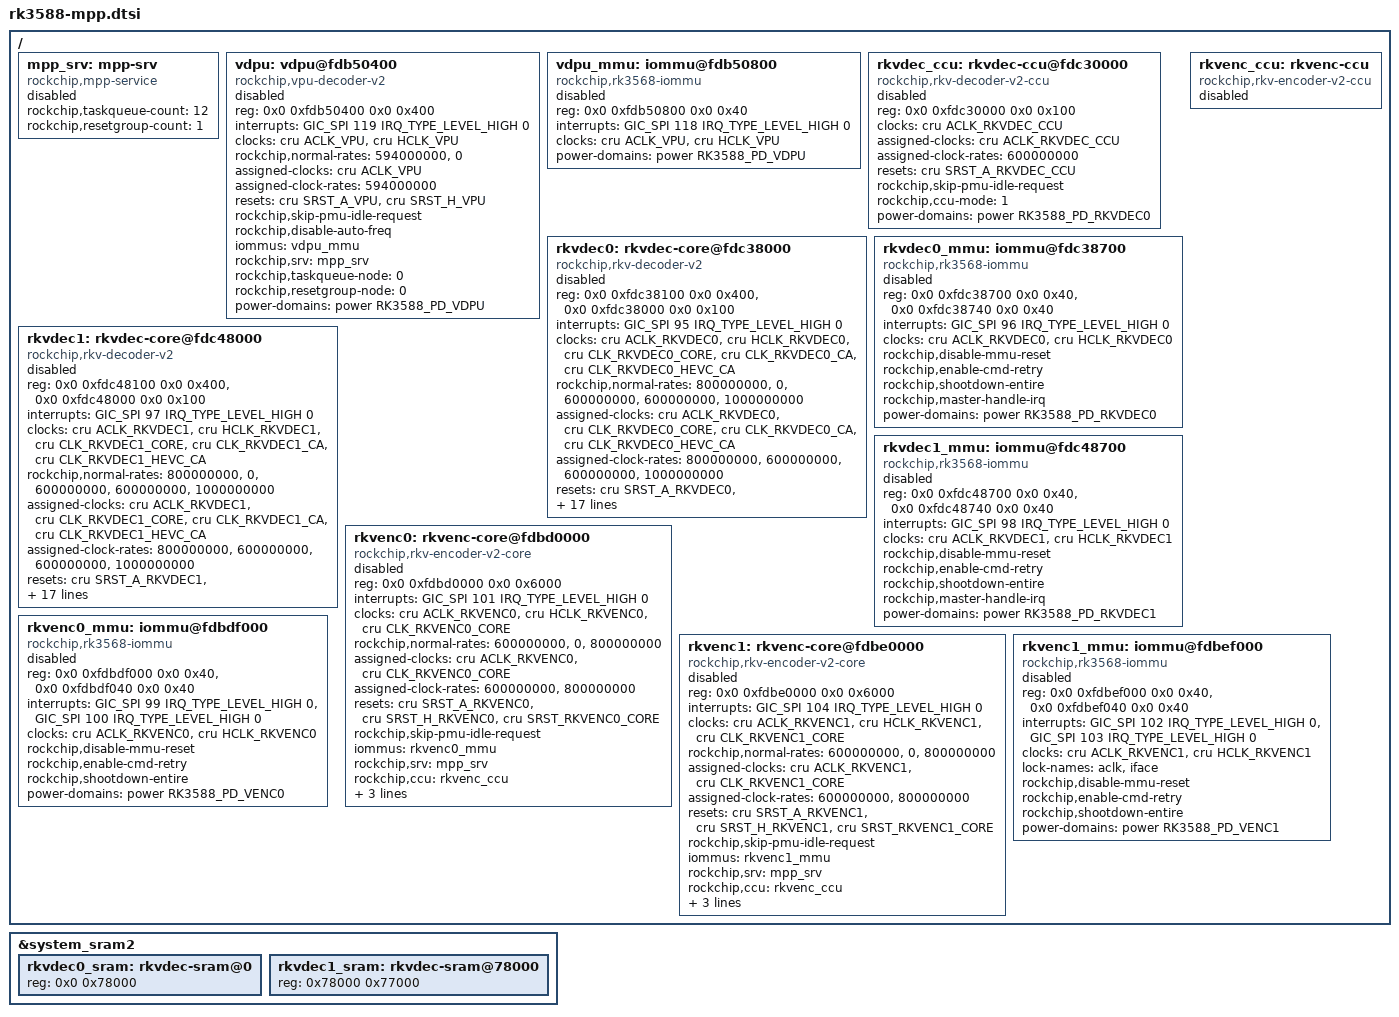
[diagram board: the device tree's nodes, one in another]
// SPDX-License-Identifier: (GPL-2.0+ OR MIT)
/ {
    mpp_srv: mpp-srv {
        compatible = "rockchip,mpp-service";
        rockchip,taskqueue-count = <12>;
        rockchip,resetgroup-count = <1>;
        status = "disabled";
    };

    vdpu: vdpu@fdb50400 {
        compatible = "rockchip,vpu-decoder-v2";
        reg = <0x0 0xfdb50400 0x0 0x400>;
        interrupts = <GIC_SPI 119 IRQ_TYPE_LEVEL_HIGH 0>;
        interrupt-names = "irq_vdpu";
        clocks = <&cru ACLK_VPU>, <&cru HCLK_VPU>;
        clock-names = "aclk_vcodec", "hclk_vcodec";
        rockchip,normal-rates = <594000000>, <0>;
        assigned-clocks = <&cru ACLK_VPU>;
        assigned-clock-rates = <594000000>;
        resets = <&cru SRST_A_VPU>, <&cru SRST_H_VPU>;
        reset-names = "shared_video_a", "shared_video_h";
        rockchip,skip-pmu-idle-request;
        rockchip,disable-auto-freq;
        iommus = <&vdpu_mmu>;
        rockchip,srv = <&mpp_srv>;
        rockchip,taskqueue-node = <0>;
        rockchip,resetgroup-node = <0>;
        power-domains = <&power RK3588_PD_VDPU>;
        status = "disabled";
    };

    vdpu_mmu: iommu@fdb50800 {
        compatible = "rockchip,rk3568-iommu";
        reg = <0x0 0xfdb50800 0x0 0x40>;
        interrupts = <GIC_SPI 118 IRQ_TYPE_LEVEL_HIGH 0>;
        interrupt-names = "irq_vdpu_mmu";
        clocks = <&cru ACLK_VPU>, <&cru HCLK_VPU>;
        clock-names = "aclk", "iface";
        power-domains = <&power RK3588_PD_VDPU>;
        #iommu-cells = <0>;
        status = "disabled";
    };

    rkvdec_ccu: rkvdec-ccu@fdc30000 {
        compatible = "rockchip,rkv-decoder-v2-ccu";
        reg = <0x0 0xfdc30000 0x0 0x100>;
        reg-names = "ccu";
        clocks = <&cru ACLK_RKVDEC_CCU>;
        clock-names = "aclk_ccu";
        assigned-clocks = <&cru ACLK_RKVDEC_CCU>;
        assigned-clock-rates = <600000000>;
        resets = <&cru SRST_A_RKVDEC_CCU>;
        reset-names = "video_ccu";
        rockchip,skip-pmu-idle-request;
        /* 1: soft ccu 2: hw ccu */
        rockchip,ccu-mode = <1>;
        power-domains = <&power RK3588_PD_RKVDEC0>;
        status = "disabled";
    };

    rkvdec0: rkvdec-core@fdc38000 {
        compatible = "rockchip,rkv-decoder-v2";
        reg = <0x0 0xfdc38100 0x0 0x400>, <0x0 0xfdc38000 0x0 0x100>;
        reg-names = "regs", "link";
        interrupts = <GIC_SPI 95 IRQ_TYPE_LEVEL_HIGH 0>;
        interrupt-names = "irq_rkvdec0";
        clocks = <&cru ACLK_RKVDEC0>, <&cru HCLK_RKVDEC0>, <&cru CLK_RKVDEC0_CORE>,
             <&cru CLK_RKVDEC0_CA>, <&cru CLK_RKVDEC0_HEVC_CA>;
        clock-names = "aclk_vcodec", "hclk_vcodec", "clk_core",
                  "clk_cabac", "clk_hevc_cabac";
        rockchip,normal-rates = <800000000>, <0>, <600000000>,
                    <600000000>, <1000000000>;
        assigned-clocks = <&cru ACLK_RKVDEC0>, <&cru CLK_RKVDEC0_CORE>,
                  <&cru CLK_RKVDEC0_CA>, <&cru CLK_RKVDEC0_HEVC_CA>;
        assigned-clock-rates = <800000000>, <600000000>,
                       <600000000>, <1000000000>;
        resets = <&cru SRST_A_RKVDEC0>, <&cru SRST_H_RKVDEC0>, <&cru SRST_RKVDEC0_CORE>,
             <&cru SRST_RKVDEC0_CA>, <&cru SRST_RKVDEC0_HEVC_CA>;
        reset-names = "video_a", "video_h", "video_core",
                  "video_cabac", "video_hevc_cabac";
        rockchip,skip-pmu-idle-request;
        iommus = <&rkvdec0_mmu>;
        rockchip,srv = <&mpp_srv>;
        rockchip,ccu = <&rkvdec_ccu>;
        rockchip,core-mask = <0x00010001>;
        rockchip,task-capacity = <16>;
        rockchip,taskqueue-node = <9>;
        rockchip,sram = <&rkvdec0_sram>;
        /* rcb_iova: start and size 1M@4095M */
        rockchip,rcb-iova = <0xFFF00000 0x100000>;
        rockchip,rcb-info = <136 24576>, <137 49152>, <141 90112>, <140 49152>,
                    <139 180224>, <133 49152>, <134 8192>, <135 4352>,
                    <138 13056>, <142 291584>;
        rockchip,rcb-min-width = <512>;
        power-domains = <&power RK3588_PD_RKVDEC0>;
        status = "disabled";
    };

    rkvdec0_mmu: iommu@fdc38700 {
        compatible = "rockchip,rk3568-iommu";
        reg = <0x0 0xfdc38700 0x0 0x40>, <0x0 0xfdc38740 0x0 0x40>;
        interrupts = <GIC_SPI 96 IRQ_TYPE_LEVEL_HIGH 0>;
        interrupt-names = "irq_rkvdec0_mmu";
        clocks = <&cru ACLK_RKVDEC0>, <&cru HCLK_RKVDEC0>;
        clock-names = "aclk", "iface";
        rockchip,disable-mmu-reset;
        rockchip,enable-cmd-retry;
        rockchip,shootdown-entire;
        rockchip,master-handle-irq;
        #iommu-cells = <0>;
        power-domains = <&power RK3588_PD_RKVDEC0>;
        status = "disabled";
    };

    rkvdec1: rkvdec-core@fdc48000 {
        compatible = "rockchip,rkv-decoder-v2";
        reg = <0x0 0xfdc48100 0x0 0x400>, <0x0 0xfdc48000 0x0 0x100>;
        reg-names = "regs", "link";
        interrupts = <GIC_SPI 97 IRQ_TYPE_LEVEL_HIGH 0>;
        interrupt-names = "irq_rkvdec1";
        clocks = <&cru ACLK_RKVDEC1>, <&cru HCLK_RKVDEC1>, <&cru CLK_RKVDEC1_CORE>,
             <&cru CLK_RKVDEC1_CA>, <&cru CLK_RKVDEC1_HEVC_CA>;
        clock-names = "aclk_vcodec", "hclk_vcodec", "clk_core",
                  "clk_cabac", "clk_hevc_cabac";
        rockchip,normal-rates = <800000000>, <0>, <600000000>,
                    <600000000>, <1000000000>;
        assigned-clocks = <&cru ACLK_RKVDEC1>, <&cru CLK_RKVDEC1_CORE>,
                  <&cru CLK_RKVDEC1_CA>, <&cru CLK_RKVDEC1_HEVC_CA>;
        assigned-clock-rates = <800000000>, <600000000>,
                       <600000000>, <1000000000>;
        resets = <&cru SRST_A_RKVDEC1>, <&cru SRST_H_RKVDEC1>, <&cru SRST_RKVDEC1_CORE>,
             <&cru SRST_RKVDEC1_CA>, <&cru SRST_RKVDEC1_HEVC_CA>;
        reset-names = "video_a", "video_h", "video_core",
                  "video_cabac", "video_hevc_cabac";
        rockchip,skip-pmu-idle-request;
        iommus = <&rkvdec1_mmu>;
        rockchip,srv = <&mpp_srv>;
        rockchip,ccu = <&rkvdec_ccu>;
        rockchip,core-mask = <0x00020002>;
        rockchip,task-capacity = <16>;
        rockchip,taskqueue-node = <9>;
        rockchip,sram = <&rkvdec1_sram>;
        /* rcb_iova: start and size 1M@4094M */
        rockchip,rcb-iova = <0xFFE00000 0x100000>;
        rockchip,rcb-info = <136 24576>, <137 49152>, <141 90112>, <140 49152>,
                    <139 180224>, <133 49152>, <134 8192>, <135 4352>,
                    <138 13056>, <142 291584>;
        rockchip,rcb-min-width = <512>;
        power-domains = <&power RK3588_PD_RKVDEC1>;
        status = "disabled";
    };

    rkvdec1_mmu: iommu@fdc48700 {
        compatible = "rockchip,rk3568-iommu";
        reg = <0x0 0xfdc48700 0x0 0x40>, <0x0 0xfdc48740 0x0 0x40>;
        interrupts = <GIC_SPI 98 IRQ_TYPE_LEVEL_HIGH 0>;
        interrupt-names = "irq_rkvdec1_mmu";
        clocks = <&cru ACLK_RKVDEC1>, <&cru HCLK_RKVDEC1>;
        clock-names = "aclk", "iface";
        rockchip,disable-mmu-reset;
        rockchip,enable-cmd-retry;
        rockchip,shootdown-entire;
        rockchip,master-handle-irq;
        #iommu-cells = <0>;
        power-domains = <&power RK3588_PD_RKVDEC1>;
        status = "disabled";
    };
    
    rkvenc_ccu: rkvenc-ccu {
        compatible = "rockchip,rkv-encoder-v2-ccu";
        status = "disabled";
    };

    rkvenc0: rkvenc-core@fdbd0000 {
        compatible = "rockchip,rkv-encoder-v2-core";
        reg = <0x0 0xfdbd0000 0x0 0x6000>;
        interrupts = <GIC_SPI 101 IRQ_TYPE_LEVEL_HIGH 0>;
        interrupt-names = "irq_rkvenc0";
        clocks = <&cru ACLK_RKVENC0>, <&cru HCLK_RKVENC0>, <&cru CLK_RKVENC0_CORE>;
        clock-names = "aclk_vcodec", "hclk_vcodec", "clk_core";
        rockchip,normal-rates = <600000000>, <0>, <800000000>;
        assigned-clocks = <&cru ACLK_RKVENC0>, <&cru CLK_RKVENC0_CORE>;
        assigned-clock-rates = <600000000>, <800000000>;
        resets = <&cru SRST_A_RKVENC0>, <&cru SRST_H_RKVENC0>, <&cru SRST_RKVENC0_CORE>;
        reset-names = "video_a", "video_h", "video_core";
        rockchip,skip-pmu-idle-request;
        iommus = <&rkvenc0_mmu>;
        rockchip,srv = <&mpp_srv>;
        rockchip,ccu = <&rkvenc_ccu>;
        rockchip,taskqueue-node = <7>;
        rockchip,task-capacity = <8>;
        power-domains = <&power RK3588_PD_VENC0>;
        status = "disabled";
    };

    rkvenc0_mmu: iommu@fdbdf000 {
        compatible = "rockchip,rk3568-iommu";
        reg = <0x0 0xfdbdf000 0x0 0x40>, <0x0 0xfdbdf040 0x0 0x40>;
        interrupts = <GIC_SPI 99 IRQ_TYPE_LEVEL_HIGH 0>,
                 <GIC_SPI 100 IRQ_TYPE_LEVEL_HIGH 0>;
        interrupt-names = "irq_rkvenc0_mmu0", "irq_rkvenc0_mmu1";
        clocks = <&cru ACLK_RKVENC0>, <&cru HCLK_RKVENC0>;
        clock-names = "aclk", "iface";
        rockchip,disable-mmu-reset;
        rockchip,enable-cmd-retry;
        rockchip,shootdown-entire;
        #iommu-cells = <0>;
        power-domains = <&power RK3588_PD_VENC0>;
        status = "disabled";
    };

    rkvenc1: rkvenc-core@fdbe0000 {
        compatible = "rockchip,rkv-encoder-v2-core";
        reg = <0x0 0xfdbe0000 0x0 0x6000>;
        interrupts = <GIC_SPI 104 IRQ_TYPE_LEVEL_HIGH 0>;
        interrupt-names = "irq_rkvenc1";
        clocks = <&cru ACLK_RKVENC1>, <&cru HCLK_RKVENC1>, <&cru CLK_RKVENC1_CORE>;
        clock-names = "aclk_vcodec", "hclk_vcodec", "clk_core";
        rockchip,normal-rates = <600000000>, <0>, <800000000>;
        assigned-clocks = <&cru ACLK_RKVENC1>, <&cru CLK_RKVENC1_CORE>;
        assigned-clock-rates = <600000000>, <800000000>;
        resets = <&cru SRST_A_RKVENC1>, <&cru SRST_H_RKVENC1>, <&cru SRST_RKVENC1_CORE>;
        reset-names = "video_a", "video_h", "video_core";
        rockchip,skip-pmu-idle-request;
        iommus = <&rkvenc1_mmu>;
        rockchip,srv = <&mpp_srv>;
        rockchip,ccu = <&rkvenc_ccu>;
        rockchip,taskqueue-node = <7>;
        rockchip,task-capacity = <8>;
        power-domains = <&power RK3588_PD_VENC1>;
        status = "disabled";
    };

    rkvenc1_mmu: iommu@fdbef000 {
        compatible = "rockchip,rk3568-iommu";
        reg = <0x0 0xfdbef000 0x0 0x40>, <0x0 0xfdbef040 0x0 0x40>;
        interrupts = <GIC_SPI 102 IRQ_TYPE_LEVEL_HIGH 0>,
                 <GIC_SPI 103 IRQ_TYPE_LEVEL_HIGH 0>;
        interrupt-names = "irq_rkvenc1_mmu0", "irq_rkvenc1_mmu1";
        clocks = <&cru ACLK_RKVENC1>, <&cru HCLK_RKVENC1>;
        lock-names = "aclk", "iface";
        rockchip,disable-mmu-reset;
        rockchip,enable-cmd-retry;
        rockchip,shootdown-entire;
        #iommu-cells = <0>;
        power-domains = <&power RK3588_PD_VENC1>;
        status = "disabled";
    };
};

&system_sram2 {
    rkvdec0_sram: rkvdec-sram@0 {
        reg = <0x0 0x78000>;
    };
    rkvdec1_sram: rkvdec-sram@78000 {
        reg = <0x78000 0x77000>;
    };
};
